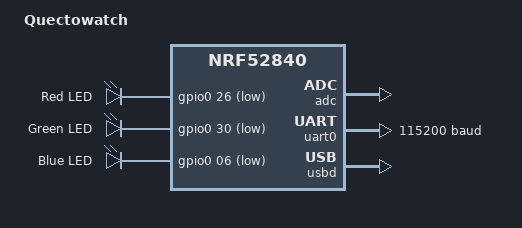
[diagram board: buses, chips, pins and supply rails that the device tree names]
// Copyright (c) 2024 Nordic Semiconductor ASA
// SPDX-License-Identifier: Apache-2.0

/dts-v1/;
#include <nordic/nrf52840_qiaa.dtsi>
#include "quectowatch-pinctrl.dtsi"

/ {
	model = "Quectowatch";
	compatible = "ed-atkinson,quectowatch";

	chosen {
		zephyr,console = &uart0;
		zephyr,sram = &sram0;
		zephyr,flash = &flash0;
		zephyr,code-partition = &slot0_partition;
	};

	/* These aliases are provided for compatibility with samples */
	aliases {
		led0 = &led0;
		led1 = &led1;
		led2 = &led2;
	};

	leds {
		compatible = "gpio-leds";
		
		led0: led_0 {
			gpios = <&gpio0 26 GPIO_ACTIVE_LOW>;
			label = "Red LED";
		};

		led1: led_1 {
			gpios = <&gpio0 30 GPIO_ACTIVE_LOW>;
			label = "Green LED";
		};

		led2: led_2 {
			gpios = <&gpio0 06 GPIO_ACTIVE_LOW>;
			label = "Blue LED";
		};
	};
};

&adc {
	status = "okay";
};

&gpiote {
	status = "okay";
};

&gpio0 {
	status = "okay";
};

&gpio1 {
	status = "okay";
};

&uart0 {
	compatible = "nordic,nrf-uarte";
	current-speed = <115200>;
	status = "okay";
	pinctrl-0 = <&uart0_default>;
	pinctrl-1 = <&uart0_sleep>;
	pinctrl-names = "default", "sleep";
};

&uart1 {
	current-speed = <1000000>;
	status = "disabled";
	pinctrl-0 = <&uart1_default>;
	pinctrl-1 = <&uart1_sleep>;
	pinctrl-names = "default", "sleep";
};

zephyr_udc0: &usbd {
	status = "okay";
};

&flash0 {
	partitions {
		compatible = "fixed-partitions";
		#address-cells = <1>;
		#size-cells = <1>;

		boot_partition: partition@0 {
			label = "mcuboot";
			reg = <0x0 0xc000>;
		};
		slot0_partition: partition@c000 {
			label = "image-0";
			reg = <0xc000 0x72000>;
		};
		slot1_partition: partition@7e000 {
			label = "image-1";
			reg = <0x7e000 0x72000>;
		};
		scratch_partition: partition@f0000 {
			label = "image-scratch";
			reg = <0xf0000 0xa000>;
		};
		storage_partition: partition@fa000 {
			label = "storage";
			reg = <0xfa000 0x6000>;
		};
	};
};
